# CCG2 register map
File version: 1.0
CPU: CM0 r1p0, little endian, no MPU, no FPU, 2 interrupt priority bits
Registers are 32-bit, read-write, reset 0x0 unless marked. A register's access mark holds for its fields unless they carry their own. Offsets are from the block's base; [hi:lo] are bit positions; {n}, {i} and the like mark numbered series; 'fields as' and 'values as' point back to an identical list.

## SCB0 (part 2 of 2)
Base 0x40050000
Same registers: SCB1 0x40060000
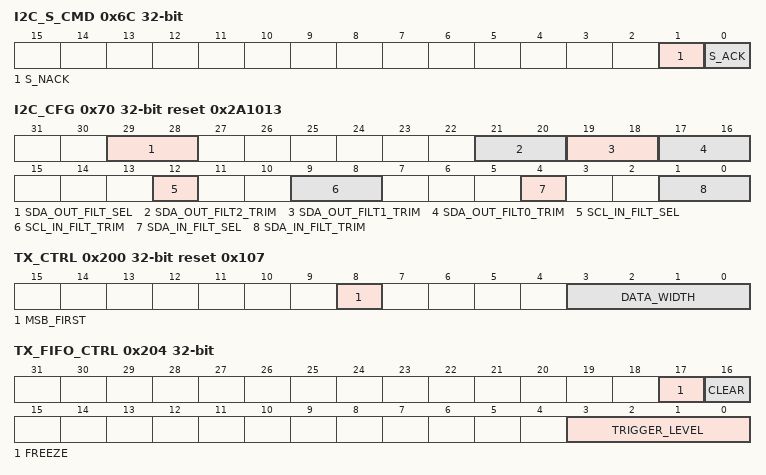
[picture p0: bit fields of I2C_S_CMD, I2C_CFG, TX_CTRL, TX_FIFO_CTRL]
0x6C I2C_S_CMD — I2C slave command register. The register fields are not retained. This is to ensure that they come up as '0' after coming out of DeepSleep system power mode.
  [1] S_NACK — When '1', attempt to transmit a negative acknowledgement (NACK). When this action is performed, the hardware sets this field to '0'. In EZ mode, this field should be set to '0' (it is only to be used in non EZ mode). This command has a higher priority than I2C_S_CMD.S_ACK, I2C_CTRL.S_READY_ADDR_ACK or I2C_CTRL.S_READY_DATA_ACK.
  [0] S_ACK — When '1', attempt to transmit an acknowledgement (ACK). When this action is performed, the hardware sets this field to '0'. In EZ mode, this field should be set to '0' (it is only to be used in non EZ mode).
0x70 I2C_CFG reset 0x2A1013 — I2C configuration register. The filters are used to remove glitches and to guarantee I2C compliant SCL and SDA setup and hold times. The filters are trimmable.
  [29:28] SDA_OUT_FILT_SEL — Selection of cumulative "i2c_sda_out" filter delay: "0": 0 ns. "1": 50 ns (filter 0 enabled). "2": 100 ns (filters 0 and 1 enabled). "3": 150 ns (filters 0, 1 and 2 enabled).
  [21:20] SDA_OUT_FILT2_TRIM — Trim bits for "i2c_sda_out" 50 ns filter 2. See s8i2cs BROS (001-59539) for more details on the trim bit values.
  [19:18] SDA_OUT_FILT1_TRIM — Trim bits for "i2c_sda_out" 50 ns filter 1. See s8i2cs BROS (001-59539) for more details on the trim bit values.
  [17:16] SDA_OUT_FILT0_TRIM — Trim bits for "i2c_sda_out" 50 ns filter 0. See s8i2cs BROS (001-59539) for more details on the trim bit values.
  [12] SCL_IN_FILT_SEL — Selection of "i2c_scl_in" filter delay: '0': 0 ns. '1: 50 ns (filter enabled).
  [9:8] SCL_IN_FILT_TRIM — Trim bits for "i2c_scl_in" 50 ns filter. See s8i2cs BROS (001-59539) for more details on the trim bit values.
  [4] SDA_IN_FILT_SEL — Selection of "i2c_sda_in" filter delay: '0': 0 ns. '1: 50 ns (filter enabled).
  [1:0] SDA_IN_FILT_TRIM — Trim bits for "i2c_sda_in" 50 ns filter. See s8i2cs BROS (001-59539) for more details on the trim bit values.
0x200 TX_CTRL reset 0x107 — Transmitter control register.
  [8] MSB_FIRST — Least significant bit first ('0') or most significant bit first ('1'). For I2C, this field should be '1'.
  [3:0] DATA_WIDTH — Dataframe width. DATA_WIDTH + 1 is the amount of bits in a transmitted data frame. This number does not include start, parity and stop bits. For UART mode, the valid range is [3, 8]. For SPI, the valid range is [3, 15]. For I2C the only valid value is 7.
0x204 TX_FIFO_CTRL — Transmitter FIFO control register.
  [17] FREEZE — When '1', hardware reads from the transmitter FIFO do not remove FIFO entries. Freeze will not advance the TX FIFO read pointer.
  [16] CLEAR — When '1', the transmitter FIFO and transmitter shift register are cleared/invalidated. Invalidation will last for as long as this field is '1'. If a quick clear/invalidation is required, the field should be set to '1' and be followed by a set to '0'. If a clear/invalidation is required for an extended time period, the field should be set to '1' during the complete time period.
  [3:0] TRIGGER_LEVEL — Trigger level. When the transmitter FIFO has less entries than the number of this field, a transmitter trigger event is generated.
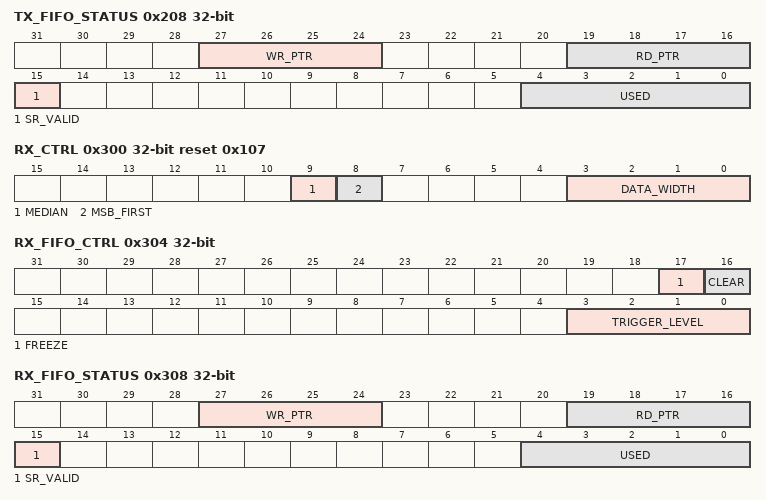
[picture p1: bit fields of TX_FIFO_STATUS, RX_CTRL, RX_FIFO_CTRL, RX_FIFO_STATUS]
0x208 TX_FIFO_STATUS — Transmitter FIFO status register. This register is not used in EZ and CMD_RESP modes.
  [27:24] WR_PTR ro — FIFO write pointer: FIFO location at which a new data frame is written.
  [19:16] RD_PTR ro — FIFO read pointer: FIFO location from which a data frame is read by the hardware.
  [15] SR_VALID ro — Indicates whether the TX shift registers holds a valid data frame ('1') or not ('0'). The shift register can be considered the top of the TX FIFO (the data frame is not included in the USED field of the TX FIFO). The shift register is a working register and holds the data frame that is currently transmitted (when the protocol state machine is transmitting a data frame) or the data frame that is tranmitted next (when the protocol state machine is not transmitting a data frame).
  [4:0] USED ro — Amount of enties in the transmitter FIFO. The value of this field ranges from 0 to FF_DATA_NR.
0x240 TX_FIFO_WR — Transmitter FIFO write register. When the IP is disabled (CTRL.ENABLED is '0') or when the TX FIFO is full, a write to this register is dropped. This register should only be used in FIFO mode (and not in EZ or CMD_RESP modes). This register is "write only"; a read from this register returns "0".
  [15:0] DATA wo — Data frame written into the transmitter FIFO. Behavior is similar to that of a PUSH operation. Note that when CTRL.BYTE_MODE is '1', only DATA[7:0] are used. A write to a full TX FIFO sets INTR_TX.OVERFLOW to '1'.
0x300 RX_CTRL reset 0x107 — Receiver control register.
  [9] MEDIAN — Median filter. When '1', a digital 3 taps median filter is performed on input interface lines. This filter should reduce the susceptability to errors. However, its requires higher oversampling values. For UART IrDA submode, this field should always be '1'.
  [8] MSB_FIRST — Least significant bit first ('0') or most significant bit first ('1'). For I2C, this field should be '1'.
  [3:0] DATA_WIDTH — Dataframe width. DATA_WIDTH + 1 is the expected amount of bits in received data frame. This number does not include start, parity and stop bits. For UART mode, the valid range is [3, 8]. For SPI, the valid range is [3, 15]. For I2C the only valid value is 7. In EZ mode (for both SPI and I2C), the only valid value is 7.
0x304 RX_FIFO_CTRL — Receiver FIFO control register.
  [17] FREEZE — When '1', hardware writes to the receiver FIFO have no effect. Freeze will not advance the RX FIFO write pointer.
  [16] CLEAR — When '1', the receiver FIFO and receiver shift register are cleared/invalidated. Invalidation will last for as long as this field is '1'. If a quick clear/invalidation is required, the field should be set to '1' and be followed by a set to '0'. If a clear/invalidation is required for an extended time period, the field should be set to '1' during the complete time period.
  [3:0] TRIGGER_LEVEL — Trigger level. When the receiver FIFO has more entries than the number of this field, a receiver trigger event is generated.
0x308 RX_FIFO_STATUS — Receiver FIFO status register. This register is not used in EZ and CMD_RESP modes.
  [27:24] WR_PTR ro — FIFO write pointer: FIFO location at which a new data frame is written by the hardware.
  [19:16] RD_PTR ro — FIFO read pointer: FIFO location from which a data frame is read.
  [15] SR_VALID ro — Indicates whether the RX shift registers holds a (partial) valid data frame ('1') or not ('0'). The shift register can be considered the bottom of the RX FIFO (the data frame is not included in the USED field of the RX FIFO). The shift register is a working register and holds the data frame that is currently being received (when the protocol state machine is receiving a data frame).
  [4:0] USED ro — Amount of enties in the receiver FIFO. The value of this field ranges from 0 to FF_DATA_NR.
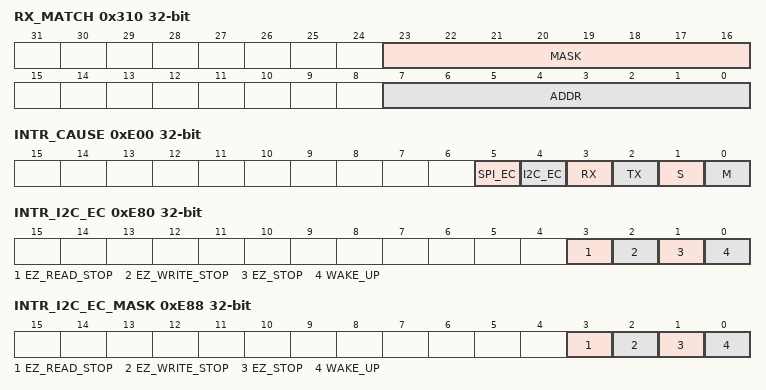
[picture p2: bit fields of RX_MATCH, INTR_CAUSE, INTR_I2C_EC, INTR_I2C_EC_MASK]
0x310 RX_MATCH — Slave address and mask register.
  [23:16] MASK — Slave device address mask. This field is a mask that specifies which of the ADDR field bits in the ADDR field take part in the matching of the slave address: MATCH = ((ADDR & MASK) == ("slave address" & MASK)).
  [7:0] ADDR — Slave device address. In UART multi-processor mode, all 8 bits are used. In I2C slave mode, only bits 7 down to 1 are used. This reflects the organization of the first transmitted byte in a I2C transfer: the first 7 bits represent the address of the addressed slave, and the last 1 bit is a read/write indicator ('0': write, '1': read).
0x340 RX_FIFO_RD reset not defined — Receiver FIFO read register. When the IP is disabled (CTRL.ENABLED is '0') or when the RX FIFO is empty, a read from this register returns 0xffff:ffff. This register should only be used in FIFO mode (and not in EZ or CMD_RESP modes). This register is "read only"; a write to this register is ignored.
  [15:0] DATA ro — Data read from the receiver FIFO. Reading a data frame will remove the data frame from the FIFO; i.e. behavior is similar to that of a POP operation. Note that when CTRL.BYTE_MODE is '1', only DATA[7:0] are used. This register has a side effect when read by software: a data frame is removed from the FIFO. This may be undesirable during debug; i.e. a read during debug should NOT have a side effect. To this end, the IP uses the AHB-Lite "hmaster[0]" input signal. When this signal is '1' in the address cycle of a bus transfer, a read transfer will not have a side effect. As a result, a read from this register will not remove a data frame from the FIFO. As a result, a read from this register behaves as a read from the SCB_RX_FIFO_RD_SILENT register. A read from an empty RX FIFO sets INTR_RX.UNDERFLOW to '1'.
0x344 RX_FIFO_RD_SILENT reset not defined — Receiver FIFO read register. When the IP is disabled (CTRL.ENABLED is '0') or when the RX FIFO is empty, a read from this register returns 0xffff:ffff. This register should only be used in FIFO mode (and not in EZ or CMD_RESP modes).
  [15:0] DATA ro — Data read from the receiver FIFO. Reading a data frame will NOT remove the data frame from the FIFO; i.e. behavior is similar to that of a PEEK operation. Note that when CTRL.BYTE_MODE is '1', only DATA[7:0] are used. A read from an empty RX FIFO sets INTR_RX.UNDERFLOW to '1'.
{0x400+4i} EZ_DATA{i} reset not defined (i=0..31) — Memory buffer registers. When the IP is disabled (CTRL.ENABLED is '0'), a read from these registers return 0xffff:ffff. It is under MMIO register control whether accesses to this register should introduce bus wait states or be discarded when the externally clocked logic is accessing the memory structure. These registers should only be used in EZ and CMD_RESP modes (and not in FIFO mode).
  [7:0] EZ_DATA — Data in buffer memory location. In case of a blocked discarded access, a read access returns 0xffff:ffff and a write access is dropped. Note that the 0xffff:ffff value is unique (not a legal EZ_DATA byte value) and can be detected by SW. Note that a discarded write access can be detected by reading back the written value.
0xE00 INTR_CAUSE — Active clocked interrupt signal register Enables software to determine the source of the combined interrupt output signals "interrupt_ic", "interrupt_ec" and "interrupt".
  [5] SPI_EC ro — Externally clocked SPI interrupt active ("interrupt_spi_ec"): INTR_SPI_EC_MASKED != 0.
  [4] I2C_EC ro — Externally clock I2C interrupt active ("interrupt_i2c_ec"): INTR_I2C_EC_MASKED != 0.
  [3] RX ro — Receiver interrupt active ("interrupt_rx"): INTR_RX_MASKED != 0.
  [2] TX ro — Transmitter interrupt active ("interrupt_tx"): INTR_TX_MASKED != 0.
  [1] S ro — Slave interrupt active ("interrupt_slave"): INTR_S_MASKED != 0.
  [0] M ro — Master interrupt active ("interrupt_master"): INTR_M_MASKED != 0.
0xE80 INTR_I2C_EC — Externally clocked I2C interrupt request register The fields in this register are set by HW and are cleared by software by writing a '1'. These interrupt causes are generated by externally clocked logic. HW clears the interrupt causes to '0', when the IP is disabled.
  [3] EZ_READ_STOP write-1-clears — STOP detection after a read transfer occurred. Activated on the end of a read transfer (I2C STOP). This event is an indication that a buffer memory location has been read from. Only available for a slave request with an address match, in EZ and CMD_RESP modes, when EC_OP is '1'.
  [2] EZ_WRITE_STOP write-1-clears — STOP detection after a write transfer occurred. Activated on the end of a write transfer (I2C STOP). This event is an indication that a buffer memory location has been written to. For EZ mode: a transfer that only writes the base address does NOT activate this event. Only available for a slave request with an address match, in EZ and CMD_RESP modes, when EC_OP is '1'.
  [1] EZ_STOP write-1-clears — STOP detection. Activated on the end of a every transfer (I2C STOP). Only available for a slave request with an address match, in EZ and CMD_RESP modes, when EC_OP is '1'.
  [0] WAKE_UP write-1-clears — Wake up request. Active on incoming slave request (with address match). Only used when EC_AM is '1'.
0xE88 INTR_I2C_EC_MASK — Externally clocked I2C interrupt mask register
  [3] EZ_READ_STOP — Mask bit for corresponding bit in interrupt request register.
  [2] EZ_WRITE_STOP — Mask bit for corresponding bit in interrupt request register.
  [1] EZ_STOP — Mask bit for corresponding bit in interrupt request register.
  [0] WAKE_UP — Mask bit for corresponding bit in interrupt request register.
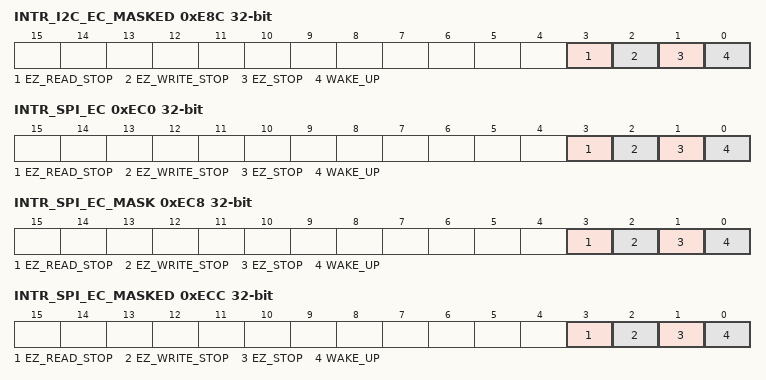
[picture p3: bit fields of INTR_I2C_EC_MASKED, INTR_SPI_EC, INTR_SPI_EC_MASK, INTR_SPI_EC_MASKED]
0xE8C INTR_I2C_EC_MASKED — Externally clocked I2C interrupt masked register When read, this register reflects a bitwise and between the interrupt request and mask registers. This register allows SW to read the status of all mask enabled interrupt causes with a single load operation, rather than two load operations: one for the interrupt causes and one for the masks. This simplifies Firmware development. The associated interrupt is active ('1'), when INTR_I2C_EC_MASKED != 0.
  [3] EZ_READ_STOP ro — Logical and of corresponding request and mask bits.
  [2] EZ_WRITE_STOP ro — Logical and of corresponding request and mask bits.
  [1] EZ_STOP ro — Logical and of corresponding request and mask bits.
  [0] WAKE_UP ro — Logical and of corresponding request and mask bits.
0xEC0 INTR_SPI_EC — Externally clocked SPI interrupt request register The fields in this register are set by HW and are cleared by software by writing a '1'. These interrupt causes are generated by externally clocked logic. HW clears the interrupt causes to '0', when the IP is disabled.
  [3] EZ_READ_STOP write-1-clears — STOP detection after a read transfer occurred. Activated on the end of a read transfer (SPI deselection). This event is an indication that a buffer memory location has been read from. Only used in EZ and CMD_RESP modes and when EC_OP is '1'.
  [2] EZ_WRITE_STOP write-1-clears — STOP detection after a write transfer occurred. Activated on the end of a write transfer (SPI deselection). This event is an indication that a buffer memory location has been written to. For EZ mode: a transfer that only writes the base address does NOT activate this event. Only used in EZ and CMD_RESP modes and when EC_OP is '1'.
  [1] EZ_STOP write-1-clears — STOP detection. Activated on the end of a every transfer (SPI deselection). Only available in EZ and CMD_RESP mode and when EC_OP is '1'.
  [0] WAKE_UP write-1-clears — Wake up request. Active on incoming slave request when externally clocked selection is '1'. Only used when EC_AM is '1'.
0xEC8 INTR_SPI_EC_MASK — Externally clocked SPI interrupt mask register
  fields as INTR_I2C_EC_MASK
0xECC INTR_SPI_EC_MASKED — Externally clocked SPI interrupt masked register When read, this register reflects a bitwise and between the interrupt request and mask registers. This register allows SW to read the status of all mask enabled interrupt causes with a single load operation, rather than two load operations: one for the interrupt causes and one for the masks. This simplifies Firmware development. The associated interrupt is active ('1'), when INTR_SPI_EC_MASKED != 0.
  fields as INTR_I2C_EC_MASKED
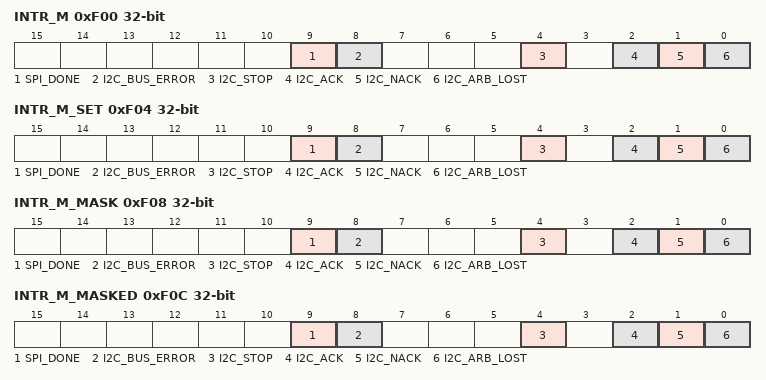
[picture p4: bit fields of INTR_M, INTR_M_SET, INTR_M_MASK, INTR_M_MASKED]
0xF00 INTR_M — Master interrupt request register. The register fields are not retained In DeepSleep power mode: HW clears the interrupt causes to '0', when coming out of DeepSleep power mode. In addition, HW clears the interrupt causes to '0', when the IP is disabled. As a result, the interrupt causes are only available in Active/Sleep power modes; they are generated by internally clocked logic (this logic operates on a clock that is only available in Active/Sleep power modes). The interrupt causes should only be used for internally clocked operation; i.e. EC_OP is '0'.
  [9] SPI_DONE write-1-clears — SPI master transfer done event: all data frames in the transmit FIFO are sent and the transmit FIFO is empty.
  [8] I2C_BUS_ERROR write-1-clears — I2C master bus error (unexpected detection of START or STOP condition).
  [4] I2C_STOP write-1-clears — I2C master STOP. Set to '1', when the master has transmitted a STOP.
  [2] I2C_ACK write-1-clears — I2C master acknowledgement. Set to '1', when the master receives a ACK (typically after the master transmitted the slave address or TX data).
  [1] I2C_NACK write-1-clears — I2C master negative acknowledgement. Set to '1', when the master receives a NACK (typically after the master transmitted the slave address or TX data).
  [0] I2C_ARB_LOST write-1-clears — I2C master lost arbitration: the value driven by the master on the SDA line is not the same as the value observed on the SDA line.
0xF04 INTR_M_SET — Master interrupt set request register When read, this register reflects the interrupt request register.
  [9] SPI_DONE write-1-sets — Write with '1' to set corresponding bit in interrupt request register.
  [8] I2C_BUS_ERROR write-1-sets — Write with '1' to set corresponding bit in interrupt request register.
  [4] I2C_STOP write-1-sets — Write with '1' to set corresponding bit in interrupt request register.
  [2] I2C_ACK write-1-sets — Write with '1' to set corresponding bit in interrupt request register.
  [1] I2C_NACK write-1-sets — Write with '1' to set corresponding bit in interrupt request register.
  [0] I2C_ARB_LOST write-1-sets — Write with '1' to set corresponding bit in interrupt request register.
0xF08 INTR_M_MASK — Master interrupt mask register.
  [9] SPI_DONE — Mask bit for corresponding bit in interrupt request register.
  [8] I2C_BUS_ERROR — Mask bit for corresponding bit in interrupt request register.
  [4] I2C_STOP — Mask bit for corresponding bit in interrupt request register.
  [2] I2C_ACK — Mask bit for corresponding bit in interrupt request register.
  [1] I2C_NACK — Mask bit for corresponding bit in interrupt request register.
  [0] I2C_ARB_LOST — Mask bit for corresponding bit in interrupt request register.
0xF0C INTR_M_MASKED — Master interrupt masked request register When read, this register reflects a bitwise and between the interrupt request and mask registers. This register allows SW to read the status of all mask enabled interrupt causes with a single load operation, rather than two load operations: one for the interrupt causes and one for the masks. This simplifies Firmware development. The associated interrupt is active ('1'), when INTR_M_MASKED != 0.
  [9] SPI_DONE ro — Logical and of corresponding request and mask bits.
  [8] I2C_BUS_ERROR ro — Logical and of corresponding request and mask bits.
  [4] I2C_STOP ro — Logical and of corresponding request and mask bits.
  [2] I2C_ACK ro — Logical and of corresponding request and mask bits.
  [1] I2C_NACK ro — Logical and of corresponding request and mask bits.
  [0] I2C_ARB_LOST ro — Logical and of corresponding request and mask bits.
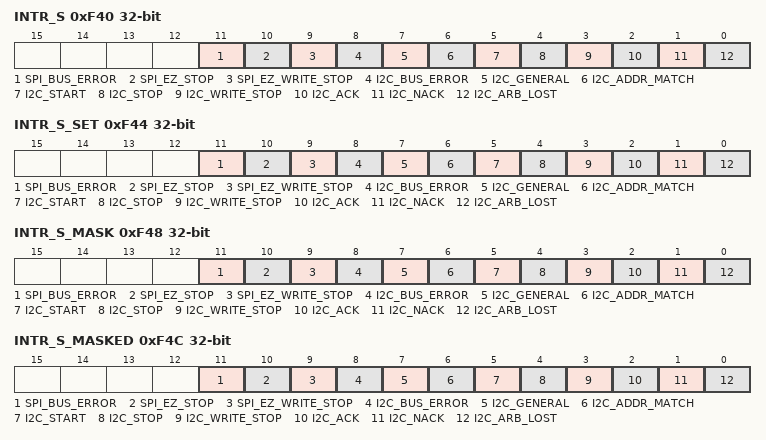
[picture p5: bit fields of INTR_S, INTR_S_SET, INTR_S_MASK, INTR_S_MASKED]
0xF40 INTR_S — Slave interrupt request register. The register fields are not retained In DeepSleep power mode: HW clears the interrupt causes to '0', when coming out of DeepSleep power mode. In addition, HW clears the interrupt causes to '0', when the IP is disabled. As a result, the interrupt causes are only available in Active/Sleep power modes; they are generated by internally clocked logic (this logic operates on a clock that is only available in Active/Sleep power modes). The interrupt causes should only be used for internally clocked operation; i.e. EC_OP is '0'.
  [11] SPI_BUS_ERROR write-1-clears — SPI slave deselected at an unexpected time in the SPI transfer. The Firmware may decide to clear the TX and RX FIFOs in case of this error.
  [10] SPI_EZ_STOP write-1-clears — SPI slave deselected after any EZ SPI transfer occurred.
  [9] SPI_EZ_WRITE_STOP write-1-clears — SPI slave deselected after a write EZ SPI transfer occurred.
  [8] I2C_BUS_ERROR write-1-clears — I2C slave bus error (unexpected detection of START or STOP condition). This should not occur, it represents erroneous I2C bus behavior. In case of a bus error, the I2C slave state machine abort the ongoing transfer. The Firmware may decide to clear the TX and RX FIFOs in case of this error.
  [7] I2C_GENERAL write-1-clears — I2C slave general call address received. If CTRL.ADDR_ACCEPT, the received address 0x00 (including the R/W bit) is available in the RX FIFO. In the case of externally clocked address matching (CTRL.EC_AM_MODE is '1') and internally clocked operation (CTRL.EC_OP_MODE is '0'), this field is set when the event is detected.
  [6] I2C_ADDR_MATCH write-1-clears — I2C slave matching address received. If CTRL.ADDR_ACCEPT, the received address (including the R/W bit) is available in the RX FIFO. In the case of externally clocked address matching (CTRL.EC_AM_MODE is '1') and internally clocked operation (CTRL.EC_OP_MODE is '0'), this field is set when the event is detected.
  [5] I2C_START write-1-clears — I2C slave START received. Set to '1', when START or REPEATED START event is detected. In the case of externally clocked address matching (CTRL.EC_AM_MODE is '1') AND clock stretching is performed (till the internally clocked logic takes over) (I2C_CTRL.S_NOT_READY_ADDR_NACK is '0'), this field is NOT set. The Firmware should use INTR_S_EC.WAKE_UP, INTR_S.I2C_ADDR_MATCH and INTR_S.I2C_GENERAL.
  [4] I2C_STOP write-1-clears — I2C STOP event for I2C (read or write) transfer intended for this slave (address matching is performed). Set to '1', when STOP or REPEATED START event is detected. The REPEATED START event is included in this interrupt cause such that the I2C transfers separated by a REPEATED START can be distinguished and potentially treated separately by the Firmware. Note that the second I2C transfer (after a REPEATED START) may be to a different slave address. The event is detected on any I2C transfer intended for this slave. Note that a I2C address intended for the slave (address is matching) will result in a I2C_STOP event independent of whether the I2C address is ACK'd or NACK'd.
  [3] I2C_WRITE_STOP write-1-clears — I2C STOP event for I2C write transfer intended for this slave (address matching is performed). Set to '1', when STOP or REPEATED START event is detected. The REPEATED START event is included in this interrupt cause such that the I2C transfers separated by a REPEATED START can be distinguished and potentially treated separately by the Firmware. Note that the second I2C transfer (after a REPEATED START) may be to a different slave address. In non EZ mode, the event is detected on any I2C write transfer intended for this slave. Note that a I2C write address intended for the slave (address is matching and a it is a write transfer) will result in a I2C_WRITE_STOP event independent of whether the I2C address is ACK'd or NACK'd. In EZ mode, the event is detected only on I2C write transfers that have EZ data written to the memory structure (an I2C write transfer that only communicates an I2C address and EZ address, will not result in this event being detected).
  [2] I2C_ACK write-1-clears — I2C slave acknowledgement received. Set to '1', when the slave receives a ACK (typically after the slave transmitted TX data).
  [1] I2C_NACK write-1-clears — I2C slave negative acknowledgement received. Set to '1', when the slave receives a NACK (typically after the slave transmitted TX data).
  [0] I2C_ARB_LOST write-1-clears — I2C slave lost arbitration: the value driven on the SDA line is not the same as the value observed on the SDA line (while the SCL line is '1'). This should not occur, it represents erroneous I2C bus behavior. In case of lost arbitration, the I2C slave state machine abort the ongoing transfer. The Firmware may decide to clear the TX and RX FIFOs in case of this error.
0xF44 INTR_S_SET — Slave interrupt set request register. When read, this register reflects the interrupt request register.
  [11] SPI_BUS_ERROR write-1-sets — Write with '1' to set corresponding bit in interrupt request register.
  [10] SPI_EZ_STOP write-1-sets — Write with '1' to set corresponding bit in interrupt request register.
  [9] SPI_EZ_WRITE_STOP write-1-sets — Write with '1' to set corresponding bit in interrupt request register.
  [8] I2C_BUS_ERROR write-1-sets — Write with '1' to set corresponding bit in interrupt request register.
  [7] I2C_GENERAL write-1-sets — Write with '1' to set corresponding bit in interrupt request register.
  [6] I2C_ADDR_MATCH write-1-sets — Write with '1' to set corresponding bit in interrupt request register.
  [5] I2C_START write-1-sets — Write with '1' to set corresponding bit in interrupt request register.
  [4] I2C_STOP write-1-sets — Write with '1' to set corresponding bit in interrupt request register.
  [3] I2C_WRITE_STOP write-1-sets — Write with '1' to set corresponding bit in interrupt request register.
  [2] I2C_ACK write-1-sets — Write with '1' to set corresponding bit in interrupt request register.
  [1] I2C_NACK write-1-sets — Write with '1' to set corresponding bit in interrupt request register.
  [0] I2C_ARB_LOST write-1-sets — Write with '1' to set corresponding bit in interrupt request register.
0xF48 INTR_S_MASK — Slave interrupt mask register.
  [11] SPI_BUS_ERROR — Mask bit for corresponding bit in interrupt request register.
  [10] SPI_EZ_STOP — Mask bit for corresponding bit in interrupt request register.
  [9] SPI_EZ_WRITE_STOP — Mask bit for corresponding bit in interrupt request register.
  [8] I2C_BUS_ERROR — Mask bit for corresponding bit in interrupt request register.
  [7] I2C_GENERAL — Mask bit for corresponding bit in interrupt request register.
  [6] I2C_ADDR_MATCH — Mask bit for corresponding bit in interrupt request register.
  [5] I2C_START — Mask bit for corresponding bit in interrupt request register.
  [4] I2C_STOP — Mask bit for corresponding bit in interrupt request register.
  [3] I2C_WRITE_STOP — Mask bit for corresponding bit in interrupt request register.
  [2] I2C_ACK — Mask bit for corresponding bit in interrupt request register.
  [1] I2C_NACK — Mask bit for corresponding bit in interrupt request register.
  [0] I2C_ARB_LOST — Mask bit for corresponding bit in interrupt request register.
0xF4C INTR_S_MASKED — Slave interrupt masked request register When read, this register reflects a bitwise and between the interrupt request and mask registers. This register allows SW to read the status of all mask enabled interrupt causes with a single load operation, rather than two load operations: one for the interrupt causes and one for the masks. This simplifies Firmware development. The associated interrupt is active ('1'), when INTR_S_MASKED != 0.
  [11] SPI_BUS_ERROR ro — Logical and of corresponding request and mask bits.
  [10] SPI_EZ_STOP ro — Logical and of corresponding request and mask bits.
  [9] SPI_EZ_WRITE_STOP ro — Logical and of corresponding request and mask bits.
  [8] I2C_BUS_ERROR ro — Logical and of corresponding request and mask bits.
  [7] I2C_GENERAL ro — Logical and of corresponding request and mask bits.
  [6] I2C_ADDR_MATCH ro — Logical and of corresponding request and mask bits.
  [5] I2C_START ro — Logical and of corresponding request and mask bits.
  [4] I2C_STOP ro — Logical and of corresponding request and mask bits.
  [3] I2C_WRITE_STOP ro — Logical and of corresponding request and mask bits.
  [2] I2C_ACK ro — Logical and of corresponding request and mask bits.
  [1] I2C_NACK ro — Logical and of corresponding request and mask bits.
  [0] I2C_ARB_LOST ro — Logical and of corresponding request and mask bits.
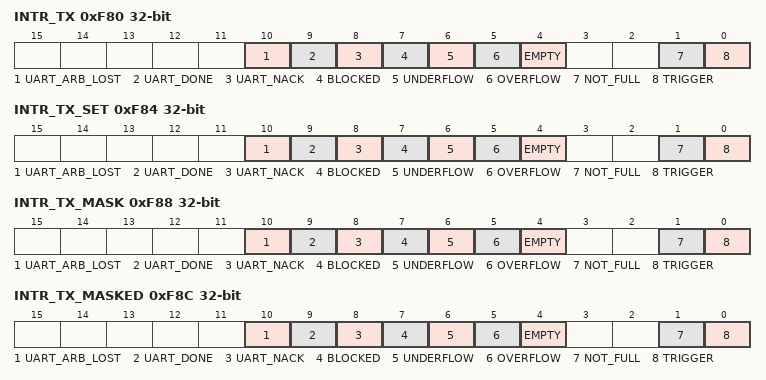
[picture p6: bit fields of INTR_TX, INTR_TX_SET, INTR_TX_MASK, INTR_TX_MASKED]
0xF80 INTR_TX — Transmitter interrupt request register. The register fields are not retained In DeepSleep power mode: HW clears the interrupt causes to '0', when coming out of DeepSleep power mode. In addition, HW clears the interrupt causes to '0', when the IP is disabled. As a result, the interrupt causes are only available in Active/Sleep power modes; they are generated by internally clocked logic (this logic operates on a clock that is only available in Active/Sleep power modes).
  [10] UART_ARB_LOST write-1-clears — UART lost arbitration: the value driven on the TX line is not the same as the value observed on the RX line. This condition event is usefull when transmitter and receiver share a TX/RX line. This is the case in LIN or SmartCard modes. Set to '1', when event is detected. Write with '1' to clear bit.
  [9] UART_DONE write-1-clears — UART transmitter done event. This happens when the IP is done transferring all data in the TX FIFO; i.e. EMPTY is '1'. Set to '1', when event is detected. Write with '1' to clear bit.
  [8] UART_NACK write-1-clears — UART transmitter received a negative acknowledgement in SmartCard mode. Set to '1', when event is detected. Write with '1' to clear bit.
  [7] BLOCKED write-1-clears — AHB-Lite write transfer can not get access to the EZ memory (EZ data access), due to an externally clocked EZ access. This may happen when STATUS.EC_BUSY is '1'.
  [6] UNDERFLOW write-1-clears — Attempt to read from an empty TX FIFO. This happens when the IP is ready to transfer data and EMPTY is '1'. Only used in FIFO mode.
  [5] OVERFLOW write-1-clears — Attempt to write to a full TX FIFO. Only used in FIFO mode.
  [4] EMPTY write-1-clears — TX FIFO is empty; i.e. it has 0 entries. Only used in FIFO mode.
  [1] NOT_FULL write-1-clears — TX FIFO is not full. Dependent on CTRL.BYTE_MODE: BYTE_MODE is '0': # entries != FF_DATA_NR/2. BYTE_MODE is '1': # entries != FF_DATA_NR. Only used in FIFO mode.
  [0] TRIGGER write-1-clears — Less entries in the TX FIFO than the value specified by TX_FIFO_CTRL. Only used in FIFO mode.
0xF84 INTR_TX_SET — Transmitter interrupt set request register When read, this register reflects the interrupt request register.
  [10] UART_ARB_LOST write-1-sets — Write with '1' to set corresponding bit in interrupt request register.
  [9] UART_DONE write-1-sets — Write with '1' to set corresponding bit in interrupt request register.
  [8] UART_NACK write-1-sets — Write with '1' to set corresponding bit in interrupt request register.
  [7] BLOCKED write-1-sets — Write with '1' to set corresponding bit in interrupt request register.
  [6] UNDERFLOW write-1-sets — Write with '1' to set corresponding bit in interrupt request register.
  [5] OVERFLOW write-1-sets — Write with '1' to set corresponding bit in interrupt request register.
  [4] EMPTY write-1-sets — Write with '1' to set corresponding bit in interrupt request register.
  [1] NOT_FULL write-1-sets — Write with '1' to set corresponding bit in interrupt request register.
  [0] TRIGGER write-1-sets — Write with '1' to set corresponding bit in interrupt request register.
0xF88 INTR_TX_MASK — Transmitter interrupt mask register.
  [10] UART_ARB_LOST — Mask bit for corresponding bit in interrupt request register.
  [9] UART_DONE — Mask bit for corresponding bit in interrupt request register.
  [8] UART_NACK — Mask bit for corresponding bit in interrupt request register.
  [7] BLOCKED — Mask bit for corresponding bit in interrupt request register.
  [6] UNDERFLOW — Mask bit for corresponding bit in interrupt request register.
  [5] OVERFLOW — Mask bit for corresponding bit in interrupt request register.
  [4] EMPTY — Mask bit for corresponding bit in interrupt request register.
  [1] NOT_FULL — Mask bit for corresponding bit in interrupt request register.
  [0] TRIGGER — Mask bit for corresponding bit in interrupt request register.
0xF8C INTR_TX_MASKED — Transmitter interrupt masked request register When read, this register reflects a bitwise and between the interrupt request and mask registers. This register allows SW to read the status of all mask enabled interrupt causes with a single load operation, rather than two load operations: one for the interrupt causes and one for the masks. This simplifies Firmware development. The associated interrupt is active ('1'), when INTR_TX_MASKED != 0.
  [10] UART_ARB_LOST ro — Logical and of corresponding request and mask bits.
  [9] UART_DONE ro — Logical and of corresponding request and mask bits.
  [8] UART_NACK ro — Logical and of corresponding request and mask bits.
  [7] BLOCKED ro — Logical and of corresponding request and mask bits.
  [6] UNDERFLOW ro — Logical and of corresponding request and mask bits.
  [5] OVERFLOW ro — Logical and of corresponding request and mask bits.
  [4] EMPTY ro — Logical and of corresponding request and mask bits.
  [1] NOT_FULL ro — Logical and of corresponding request and mask bits.
  [0] TRIGGER ro — Logical and of corresponding request and mask bits.
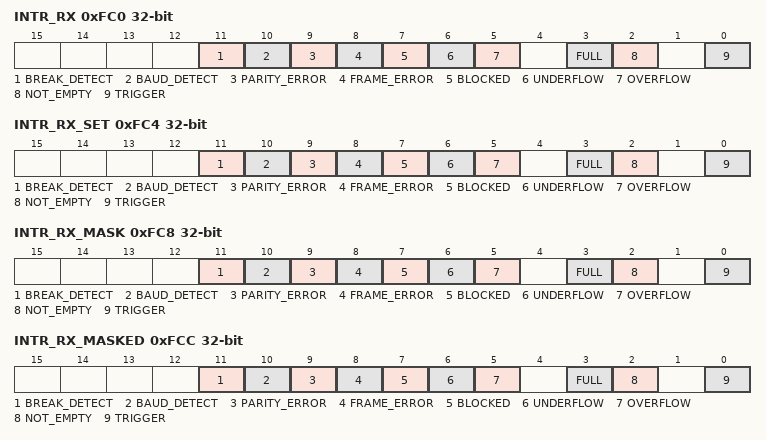
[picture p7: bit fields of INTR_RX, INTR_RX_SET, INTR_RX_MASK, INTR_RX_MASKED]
0xFC0 INTR_RX — Receiver interrupt request register. The register fields are not retained In DeepSleep power mode: HW clears the interrupt causes to '0', when coming out of DeepSleep power mode. In addition, HW clears the interrupt causes to '0', when the IP is disabled. As a result, the interrupt causes are only available in Active/Sleep power modes; they are generated by internally clocked logic (this logic operates on a clock that is only available in Active/Sleep power modes).
  [11] BREAK_DETECT write-1-clears — Break detection is successful: the line is '0' for UART_RX_CTRL.BREAK_WIDTH + 1 bit period. Can occur at any time to address unanticipated break fields; i.e. "break-in-data" is supported. This feature is supported for the UART standard and LIN submodes. For the UART standard submodes, ongoing receipt of data frames is NOT affected; i.e. Firmware is ecpected to take the proper action. For the LIN submode, possible ongoing receipt of a data frame is stopped and the (partially) received data frame is dropped and baud rate detection is started. Set to '1', when event is detected. Write with '1' to clear bit.
  [10] BAUD_DETECT write-1-clears — LIN baudrate detection is completed. The receiver software uses the UART_RX_STATUS.BR_COUNTER value to set the right IP clock (from the programmable clock IP) to guarantee successful receipt of the first LIN data frame (Protected Identifier Field) after the synchronization byte. Set to '1', when event is detected. Write with '1' to clear bit.
  [9] PARITY_ERROR write-1-clears — Parity error in received data frame. Set to '1', when event is detected. Write with '1' to clear bit. If UART_RX_CTL.DROP_ON_PARITY_ERROR is '1', the received frame is dropped. If UART_RX_CTL.DROP_ON_PARITY_ERROR is '0', the received frame is send to the RX FIFO. In SmartCard submode, negatively acknowledged data frames generate a parity error. Note that Firmware can only identify the erroneous data frame in the RX FIFO if it is fast enough to read the data frame before the hardware writes a next data frame into the RX FIFO.
  [8] FRAME_ERROR write-1-clears — Frame error in received data frame. Set to '1', when event is detected. Write with '1' to clear bit. This can be either a start or stop bit(s) error: Start bit error: after the detection of the beginning of a start bit period (RX line changes from '1' to '0'), the middle of the start bit period is sampled erroneously (RX line is '1'). Note: a start bit error is detected BEFORE a data frame is received. Stop bit error: the RX line is sampled as '0', but a '1' was expected. Note: a stop bit error may result in failure to receive successive data frame(s). Note: a stop bit error is detected AFTER a data frame is received. A stop bit error is detected after a data frame is received, and the UART_RX_CTL.DROP_ON_FRAME_ERROR field specifies whether the received frame is dropped or send to the RX FIFO. If UART_RX_CTL.DROP_ON_FRAME_ERROR is '1', the received data frame is dropped. If UART_RX_CTL.DROP_ON_FRAME_ERROR is '0', the received data frame is send to the RX FIFO. Note that Firmware can only identify the erroneous data frame in the RX FIFO if it is fast enough to read the data frame before the hardware writes a next data frame into the RX FIFO; i.e. the RX FIFO does not have error flags to tag erroneous data frames.
  [7] BLOCKED write-1-clears — AHB-Lite read transfer can not get access to the EZ memory (EZ_DATA accesses), due to an externally clocked EZ access. This may happen when STATUS.EC_BUSY is '1'.
  [6] UNDERFLOW write-1-clears — Attempt to read from an empty RX FIFO. Only used in FIFO mode.
  [5] OVERFLOW write-1-clears — Attempt to write to a full RX FIFO. Note: in I2C mode, the OVERFLOW is set when a data frame is received and the RX FIFO is full, independent of whether it is ACK'd or NACK'd. Only used in FIFO mode.
  [3] FULL write-1-clears — RX FIFO is full. Note that received data frames are lost when the RX FIFO is full. Dependent on CTRL.BYTE_MODET: BYTE_MODE is '0': # entries == FF_DATA_NR/2. BYTE_MODE is '1': # entries == FF_DATA_NR. Only used in FIFO mode.
  [2] NOT_EMPTY write-1-clears — RX FIFO is not empty. Only used in FIFO mode.
  [0] TRIGGER write-1-clears — More entries in the RX FIFO than the value specified by TRIGGER_LEVEL in SCB_RX_FIFO_CTL. Only used in FIFO mode.
0xFC4 INTR_RX_SET — Receiver interrupt set request register. When read, this register reflects the interrupt request register.
  [11] BREAK_DETECT write-1-sets — Write with '1' to set corresponding bit in interrupt status register.
  [10] BAUD_DETECT write-1-sets — Write with '1' to set corresponding bit in interrupt status register.
  [9] PARITY_ERROR write-1-sets — Write with '1' to set corresponding bit in interrupt status register.
  [8] FRAME_ERROR write-1-sets — Write with '1' to set corresponding bit in interrupt status register.
  [7] BLOCKED write-1-sets — Write with '1' to set corresponding bit in interrupt status register.
  [6] UNDERFLOW write-1-sets — Write with '1' to set corresponding bit in interrupt status register.
  [5] OVERFLOW write-1-sets — Write with '1' to set corresponding bit in interrupt status register.
  [3] FULL write-1-sets — Write with '1' to set corresponding bit in interrupt status register.
  [2] NOT_EMPTY write-1-sets — Write with '1' to set corresponding bit in interrupt status register.
  [0] TRIGGER write-1-sets — Write with '1' to set corresponding bit in interrupt request register.
0xFC8 INTR_RX_MASK — Receiver interrupt mask register.
  [11] BREAK_DETECT — Mask bit for corresponding bit in interrupt request register.
  [10] BAUD_DETECT — Mask bit for corresponding bit in interrupt request register.
  [9] PARITY_ERROR — Mask bit for corresponding bit in interrupt request register.
  [8] FRAME_ERROR — Mask bit for corresponding bit in interrupt request register.
  [7] BLOCKED — Mask bit for corresponding bit in interrupt request register.
  [6] UNDERFLOW — Mask bit for corresponding bit in interrupt request register.
  [5] OVERFLOW — Mask bit for corresponding bit in interrupt request register.
  [3] FULL — Mask bit for corresponding bit in interrupt request register.
  [2] NOT_EMPTY — Mask bit for corresponding bit in interrupt request register.
  [0] TRIGGER — Mask bit for corresponding bit in interrupt request register.
0xFCC INTR_RX_MASKED — Receiver interrupt masked request register When read, this register reflects a bitwise and between the interrupt request and mask registers. This register allows SW to read the status of all mask enabled interrupt causes with a single load operation, rather than two load operations: one for the interrupt causes and one for the masks. This simplifies Firmware development. The associated interrupt is active ('1'), when INTR_RX_MASKED != 0.
  [11] BREAK_DETECT ro — Logical and of corresponding request and mask bits.
  [10] BAUD_DETECT ro — Logical and of corresponding request and mask bits.
  [9] PARITY_ERROR ro — Logical and of corresponding request and mask bits.
  [8] FRAME_ERROR ro — Logical and of corresponding request and mask bits.
  [7] BLOCKED ro — Logical and of corresponding request and mask bits.
  [6] UNDERFLOW ro — Logical and of corresponding request and mask bits.
  [5] OVERFLOW ro — Logical and of corresponding request and mask bits.
  [3] FULL ro — Logical and of corresponding request and mask bits.
  [2] NOT_EMPTY ro — Logical and of corresponding request and mask bits.
  [0] TRIGGER ro — Logical and of corresponding request and mask bits.
